# Cortex_M4 register map
Vendor: Arm Ltd.; Series: ARMv7E-M; File version: 1.0.0
CPU: CM4 r0p0, little endian, MPU, FPU, double-precision FPU, DSP, 8 interrupt priority bits
Registers are 32-bit, read-only, reset 0x0 unless marked. A register's access mark holds for its fields unless they carry their own. Offsets are from the block's base; [hi:lo] are bit positions; {n}, {i} and the like mark numbered series; 'fields as' and 'values as' point back to an identical list.

## MPU — Memory Protection Unit (optional): programmable regions with access permissions and memory attributes, checked on every access. ARMv6-M/v7-M (PMSAv7) use RBAR/RASR power-of-two regions; ARMv8-M (PMSAv8) uses RBAR/RLAR base-limit regions with MAIR attributes.
Base 0xE000ED90
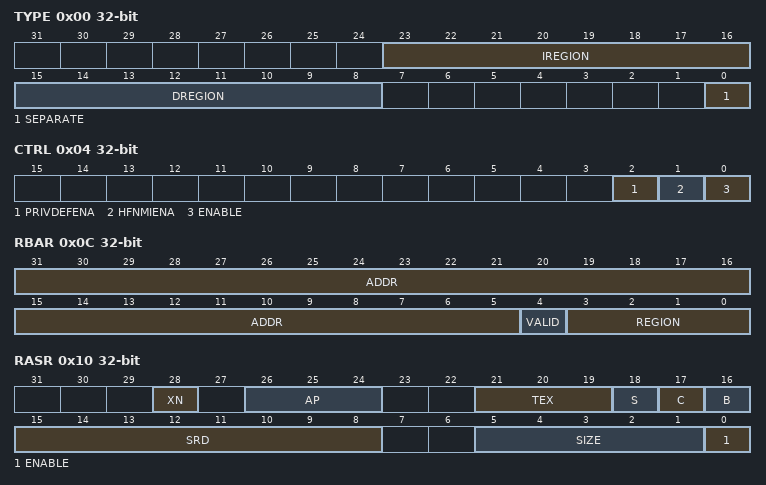
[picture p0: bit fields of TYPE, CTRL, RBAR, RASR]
0x00 TYPE — MPU Type Register: how many regions the MPU implements (0 = no MPU). Read-only.
  [23:16] IREGION — Number of instruction regions; always 0 (unified).
  [15:8] DREGION — Number of MPU regions implemented (0 = no MPU; Cortex-M cores offer 8 or 16).
  [0] SEPARATE — 0 = unified MPU (instruction and data share the regions). Always 0 on Cortex-M.
0x04 CTRL rw — MPU Control Register: global enable, behaviour during HardFault/NMI, and the privileged default memory map.
  [2] PRIVDEFENA — 1 = privileged accesses to addresses not covered by any enabled region use the default memory map; 0 = they raise a MemManage fault (unprivileged accesses always fault).
  [1] HFNMIENA — 1 = the MPU stays enabled during HardFault, NMI and FAULTMASK handlers; 0 = those handlers use the default memory map (the usual choice).
  [0] ENABLE — MPU enable. When 0 the default memory map applies to all accesses.
0x08 RNR rw — MPU Region Number Register: selects the region that RBAR and RASR/RLAR access.
  [7:0] REGION — Region number selected for RBAR/RASR (RLAR) accesses.
0x0C RBAR rw — MPU Region Base Address Register for the region selected by RNR (ARMv7-M: also selects the region when VALID is set). ARMv8-M: base address, shareability, access permissions and XN.
  [31:5] ADDR — Region base address. Must be aligned to the region size; the bits below the size (as set in RASR.SIZE) are ignored.
  [4] VALID wo — Write 1 to also write REGION into RNR in the same access, so base and number can be set with one store. Reads as 0.
  [3:0] REGION — Region number to select when VALID = 1; reads back the current RNR.
0x10 RASR rw — MPU Region Attribute and Size Register (ARMv7-M/v6-M PMSAv7): enable, power-of-two size, subregion disables and the memory attributes/permissions of the selected region.
  [28] XN — Execute never: 1 = instruction fetches from this region raise an IACCVIOL MemManage fault.
  [26:24] AP — Access permissions (privileged/unprivileged): 0 = no access, 1 = RW/no access, 2 = RW/RO, 3 = RW/RW, 5 = RO/no access, 6 or 7 = RO/RO.
    0=NoAccess; 1=PrivRW (Privileged read/write, unprivileged no access); 2=PrivRW_UserRO (Privileged read/write, unprivileged read-only); 3=FullAccess (Read/write for all); 5=PrivRO (Privileged read-only, unprivileged no access); 6=Read-only for all; 7=ReadOnly_7 (Read-only for all)
  [21:19] TEX — Type extension: 0 = standard types via C/B, 1 with C=B=0 Normal non-cacheable, 1 with C=B=1 write-back write-allocate, 2 = Device non-shareable, 4-7 = separate outer/inner cache policies in TEX[1:0] and C/B.
  [18] S — Shareable: 1 = the region is shared with other bus masters (DMA) - cacheable shared memory is treated as non-cacheable on Cortex-M7 unless CACR.SIWT is set.
  [17] C — Cacheable (see B).
  [16] B — Bufferable (with C and TEX selects the memory type: TEX=0 C=0 B=0 Strongly-ordered, B=1 Device; C=1 B=0 write-through, C=1 B=1 write-back).
  [15:8] SRD — Subregion disable: bit k = 1 disables the k-th eighth of the region (regions of 256 bytes or more). Lets a region punch holes in a larger one.
  [5:1] SIZE — Region size = 2^(SIZE+1) bytes: 4 = 32 B (minimum), 7 = 256 B, 11 = 4 KB, 19 = 1 MB, 31 = 4 GB.
  [0] ENABLE — Region enable.
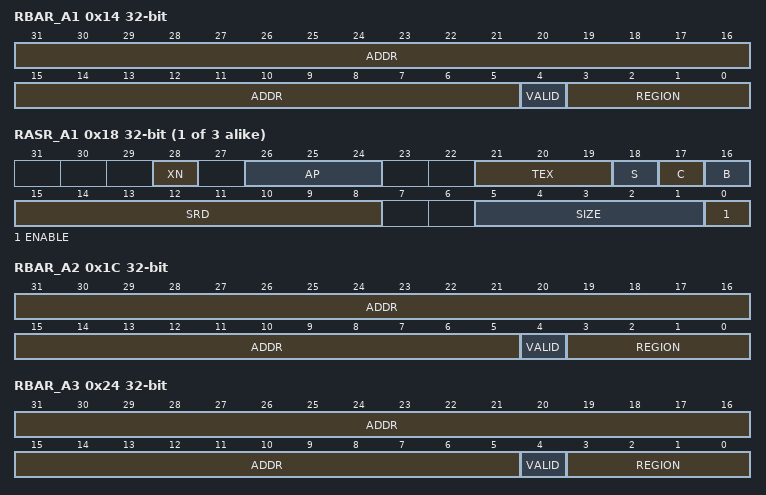
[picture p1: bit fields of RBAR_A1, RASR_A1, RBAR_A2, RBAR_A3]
0x14 RBAR_A1 rw — Alias of RBAR that accesses region RNR+1, so up to four regions can be programmed with a single STM. Same fields as RBAR.
  fields as RBAR
{0x10+8i} RASR_A{i} rw (i=1..3) — Alias of RASR that accesses region RNR+{i}. Same fields as RASR.
  fields as RASR
0x1C RBAR_A2 rw — Alias of RBAR that accesses region RNR+2. Same fields as RBAR.
  fields as RBAR
0x24 RBAR_A3 rw — Alias of RBAR that accesses region RNR+3. Same fields as RBAR.
  fields as RBAR
